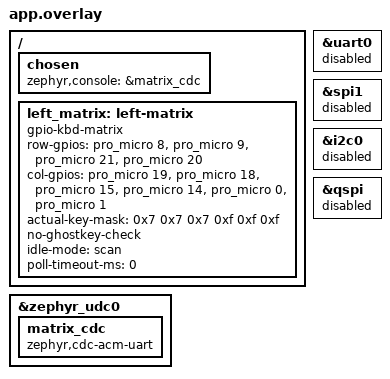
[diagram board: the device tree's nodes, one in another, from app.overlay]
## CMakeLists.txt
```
cmake_minimum_required(VERSION 3.20.0)
find_package(Zephyr REQUIRED HINTS $ENV{ZEPHYR_BASE})
project(steno_squid_left_matrix_test)
target_sources(app PRIVATE src/main.c)
```

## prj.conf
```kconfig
CONFIG_GPIO=y
CONFIG_INPUT=y
CONFIG_INPUT_MODE_SYNCHRONOUS=y

CONFIG_BUILD_OUTPUT_UF2=y
CONFIG_BUILD_OUTPUT_UF2_FAMILY_ID="0xada52840"
CONFIG_USE_DT_CODE_PARTITION=y

CONFIG_USB_DEVICE_STACK=y
CONFIG_USB_DEVICE_INITIALIZE_AT_BOOT=n
CONFIG_USB_DEVICE_PRODUCT="StenoSquid Left Matrix"
CONFIG_SERIAL=y
CONFIG_CONSOLE=y
CONFIG_UART_CONSOLE=y
CONFIG_UART_LINE_CTRL=y
```

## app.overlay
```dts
#include <zephyr/dt-bindings/gpio/gpio.h>

/ {
	chosen {
		zephyr,console = &matrix_cdc;
	};

	left_matrix: left-matrix {
		compatible = "gpio-kbd-matrix";
		row-gpios = <&pro_micro 8 (GPIO_ACTIVE_HIGH | GPIO_PULL_DOWN)>,
			    <&pro_micro 9 (GPIO_ACTIVE_HIGH | GPIO_PULL_DOWN)>,
			    <&pro_micro 21 (GPIO_ACTIVE_HIGH | GPIO_PULL_DOWN)>,
			    <&pro_micro 20 (GPIO_ACTIVE_HIGH | GPIO_PULL_DOWN)>;
		col-gpios = <&pro_micro 19 GPIO_ACTIVE_HIGH>,
			    <&pro_micro 18 GPIO_ACTIVE_HIGH>,
			    <&pro_micro 15 GPIO_ACTIVE_HIGH>,
			    <&pro_micro 14 GPIO_ACTIVE_HIGH>,
			    <&pro_micro 0 GPIO_ACTIVE_HIGH>,
			    <&pro_micro 1 GPIO_ACTIVE_HIGH>;

		/* R3 has thumb switches only at C3, C4 and C5. */
		actual-key-mask = <0x7 0x7 0x7 0xf 0xf 0xf>;
		no-ghostkey-check;
		idle-mode = "scan";
		poll-timeout-ms = <0>;
	};
};

&zephyr_udc0 {
	matrix_cdc: matrix_cdc {
		compatible = "zephyr,cdc-acm-uart";
	};
};

/* D0/D1 and the stock SPI pins belong to the matrix. */
&uart0 {
	status = "disabled";
};

&spi1 {
	status = "disabled";
};

/* I2C shares the external flash wiring. Leave that bus idle. */
&i2c0 {
	status = "disabled";
};

&qspi {
	status = "disabled";
};
```

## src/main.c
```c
#include <zephyr/device.h>
#include <zephyr/drivers/uart.h>
#include <zephyr/input/input.h>
#include <zephyr/kernel.h>
#include <zephyr/sys/printk.h>
#include <zephyr/usb/usb_device.h>

#define MATRIX_NODE DT_NODELABEL(left_matrix)
#define COLS DT_PROP_LEN(MATRIX_NODE, col_gpios)
#define KEY_COUNT 21

struct key_event {
	uint8_t row;
	uint8_t col;
	bool pressed;
};

K_MSGQ_DEFINE(key_events, sizeof(struct key_event), 32, 1);

static void matrix_event(struct input_event *event, void *user_data)
{
	static struct key_event key;

	ARG_UNUSED(user_data);
	/* The scanner sends column, row, then a synchronized touch event. */
	if (event->type == INPUT_EV_ABS && event->code == INPUT_ABS_X) {
		key.col = event->value;
	} else if (event->type == INPUT_EV_ABS && event->code == INPUT_ABS_Y) {
		key.row = event->value;
	} else if (event->type == INPUT_EV_KEY && event->code == INPUT_BTN_TOUCH &&
		   event->sync) {
		key.pressed = event->value != 0;
		k_msgq_put(&key_events, &key, K_FOREVER);
	}
}

INPUT_CALLBACK_DEFINE(DEVICE_DT_GET(MATRIX_NODE), matrix_event, NULL);

int main(void)
{
	const struct device *console = DEVICE_DT_GET(DT_CHOSEN(zephyr_console));
	uint32_t dtr = 0;
	uint32_t held = 0;
	uint32_t pressed = 0;
	uint32_t released = 0;
	struct key_event key;

	if (!device_is_ready(console) || usb_enable(NULL) != 0) {
		return -ENODEV;
	}

	while (!dtr) {
		uart_line_ctrl_get(console, UART_LINE_CTRL_DTR, &dtr);
		k_msleep(50);
	}
	if (!device_is_ready(DEVICE_DT_GET(MATRIX_NODE))) {
		printk("FAIL: left matrix scanner initialization\n");
		return -ENODEV;
	}

	printk("READY: Steno Squid left matrix, %d switches\n", KEY_COUNT);
	for (;;) {
		if (k_msgq_get(&key_events, &key, K_SECONDS(5)) == 0) {
			uint32_t bit = BIT(key.row * COLS + key.col);

			if (key.pressed) {
				held |= bit;
				pressed |= bit;
			} else {
				held &= ~bit;
				released |= bit;
			}
			printk("%s R%uC%u ", key.pressed ? "DOWN" : "UP", key.row, key.col);
		} else {
			printk("IDLE ");
		}
		printk("held=0x%06x count=%d tested=%d/%d\n", held, __builtin_popcount(held),
		       __builtin_popcount(pressed & released), KEY_COUNT);
	}
}
```
